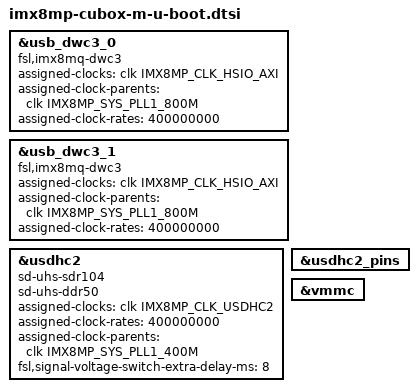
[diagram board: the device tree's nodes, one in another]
// SPDX-License-Identifier: (GPL-2.0+ OR MIT)
/*
 * Copyright 2025 Josua Mayer <josua@solid-run.com>
 */

#include "imx8mp-sr-som-u-boot.dtsi"

&usb_dwc3_0 {
	compatible = "fsl,imx8mq-dwc3", "snps,dwc3";
	assigned-clocks = <&clk IMX8MP_CLK_HSIO_AXI>;
	assigned-clock-parents = <&clk IMX8MP_SYS_PLL1_800M>;
	assigned-clock-rates = <400000000>;
};

&usb_dwc3_1 {
	compatible = "fsl,imx8mq-dwc3", "snps,dwc3";
	assigned-clocks = <&clk IMX8MP_CLK_HSIO_AXI>;
	assigned-clock-parents = <&clk IMX8MP_SYS_PLL1_800M>;
	assigned-clock-rates = <400000000>;
};

&usdhc2 {
	bootph-pre-ram;
	sd-uhs-sdr104;
	sd-uhs-ddr50;
	assigned-clocks = <&clk IMX8MP_CLK_USDHC2>;
	assigned-clock-rates = <400000000>;
	assigned-clock-parents = <&clk IMX8MP_SYS_PLL1_400M>;
	fsl,signal-voltage-switch-extra-delay-ms = <8>;
};

&usdhc2_pins {
	bootph-pre-ram;
};

&vmmc {
	bootph-pre-ram;
};
